# GD32E511_512 register map
File version: 1.0
CPU: CM33 r0p4, little endian, MPU, FPU, 4 interrupt priority bits
Registers are 32-bit, read-write, reset 0x0 unless marked. A register's access mark holds for its fields unless they carry their own. Offsets are from the block's base; [hi:lo] are bit positions.

## RCU — Reset and clock unit
Base 0x40021000
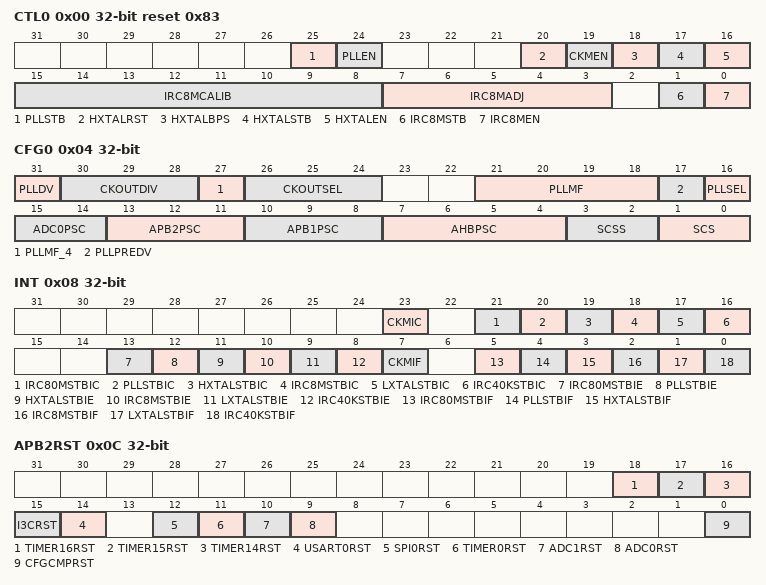
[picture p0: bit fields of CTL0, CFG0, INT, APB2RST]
0x00 CTL0 access per field reset 0x83 — Control register 0
  [25] PLLSTB ro — PLL clock stabilization flag
  [24] PLLEN rw — PLL enable
  [20] HXTALRST rw — HXTAL reset
  [19] CKMEN rw — HXTAL clock monitor enable
  [18] HXTALBPS rw — External crystal oscillator (HXTAL) clock bypass mode enable
  [17] HXTALSTB ro — External crystal oscillator (HXTAL) clock stabilization flag
  [16] HXTALEN rw — External high speed oscillator enable
  [15:8] IRC8MCALIB ro — Internal 8M RC oscillator calibration value register
  [7:3] IRC8MADJ rw — Internal 8M RC oscillator clock trim adjust value
  [1] IRC8MSTB ro — IRC8M high speed internal oscillator stabilization flag
  [0] IRC8MEN rw — Internal high speed oscillator enable
0x04 CFG0 access per field — Configuration register 0
  [31] PLLDV rw — The CK_PLL divide by 1 or 2 for CK_OUT
  [30:28] CKOUTDIV rw — The CK_OUT divider which the CK_OUT frequency can be reduced,
  [27] PLLMF_4 rw — Bit 4 of PLLMF register
  [26:24] CKOUTSEL rw — CK_OUT clock source selection
  [21:18] PLLMF rw — PLL multiply factor
  [17] PLLPREDV rw — HXTAL divider for PLL source clock selection. This bit is the same bit as bit PREDV[0] from RCU_CFG1. Refer to RCU_CFG1 PREDV bits description.
  [16] PLLSEL rw — PLL clock source selection
  [15:14] ADC0PSC rw — ADC0 clock prescaler selection
  [13:11] APB2PSC rw — APB2 prescaler selection
  [10:8] APB1PSC rw — APB1 prescaler selection
  [7:4] AHBPSC rw — AHB prescaler selection
  [3:2] SCSS ro — System clock switch status
  [1:0] SCS rw — System clock switch
0x08 INT access per field — Interrupt register
  [23] CKMIC wo — HXTAL clock stuck interrupt clear
  [21] IRC80MSTBIC wo — IRC80M stabilization interrupt clear
  [20] PLLSTBIC wo — PLL stabilization interrupt clear
  [19] HXTALSTBIC wo — HXTAL stabilization interrupt clear
  [18] IRC8MSTBIC wo — IRC8M stabilization interrupt clear
  [17] LXTALSTBIC wo — LXTAL stabilization interrupt clear
  [16] IRC40KSTBIC wo — IRC40K stabilization interrupt clear
  [13] IRC80MSTBIE rw — IRC80M stabilization interrupt enable
  [12] PLLSTBIE rw — PLL stabilization interrupt enable
  [11] HXTALSTBIE rw — HXTAL stabilization interrupt enable
  [10] IRC8MSTBIE rw — IRC8M stabilization interrupt enable
  [9] LXTALSTBIE rw — LXTAL stabilization interrupt enable
  [8] IRC40KSTBIE rw — IRC40K stabilization interrupt enable
  [7] CKMIF ro — HXTAL clock stuck interrupt flag
  [5] IRC80MSTBIF ro — IRC80M stabilization interrupt flag
  [4] PLLSTBIF ro — PLL stabilization interrupt flag
  [3] HXTALSTBIF ro — HXTAL stabilization interrupt flag
  [2] IRC8MSTBIF ro — IRC8M stabilization interrupt flag
  [1] LXTALSTBIF ro — LXTAL stabilization interrupt flag
  [0] IRC40KSTBIF ro — IRC40K stabilization interrupt flag
0x0C APB2RST — APB2 reset register
  [18] TIMER16RST — TIMER16 reset
  [17] TIMER15RST — TIMER15 reset
  [16] TIMER14RST — TIMER14 reset
  [15] I3CRST — I3C Reset
  [14] USART0RST — USART0 Reset
  [12] SPI0RST — SPI0 Reset
  [11] TIMER0RST — TIMER0 reset
  [10] ADC1RST — ADC1 reset
  [9] ADC0RST — ADC0 reset
  [0] CFGCMPRST — System configuration and comparator reset
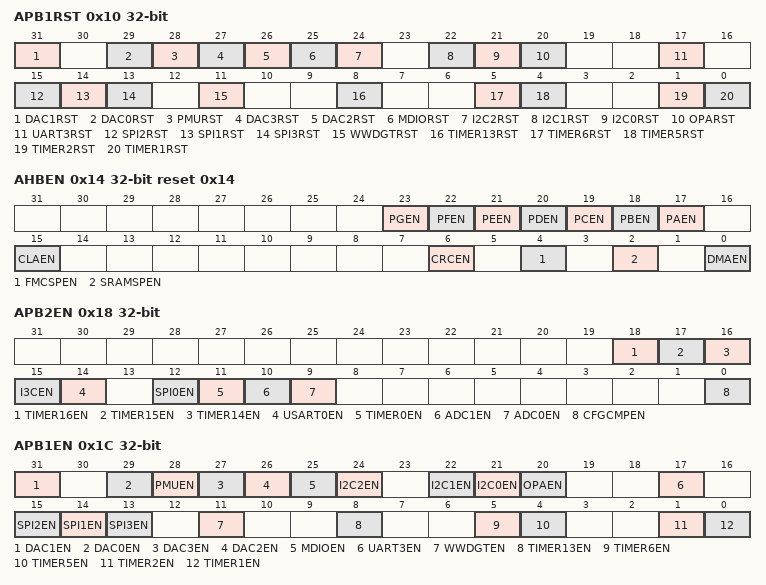
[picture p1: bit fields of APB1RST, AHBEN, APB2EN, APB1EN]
0x10 APB1RST — APB1 reset register
  [31] DAC1RST — DAC1 reset
  [29] DAC0RST — DAC0 reset
  [28] PMURST — Power control reset
  [27] DAC3RST — DAC3 reset
  [26] DAC2RST — DAC2 reset
  [25] MDIORST — MDIO reset
  [24] I2C2RST — I2C2 reset
  [22] I2C1RST — I2C1 reset
  [21] I2C0RST — I2C0 reset
  [20] OPARST — OPA reset
  [17] UART3RST — UART3 reset
  [15] SPI2RST — SPI2 reset
  [14] SPI1RST — SPI1 reset
  [13] SPI3RST — SPI3 reset
  [11] WWDGTRST — Window watchdog timer reset
  [8] TIMER13RST — TIMER13 timer reset
  [5] TIMER6RST — TIMER6 timer reset
  [4] TIMER5RST — TIMER5 timer reset
  [1] TIMER2RST — TIMER2 timer reset
  [0] TIMER1RST — TIMER1 timer reset
0x14 AHBEN reset 0x14 — AHB enable register
  [23] PGEN — GPIO port G clock enable
  [22] PFEN — GPIO port F clock enable
  [21] PEEN — GPIO port E clock enable
  [20] PDEN — GPIO port D clock enable
  [19] PCEN — GPIO port C clock enable
  [18] PBEN — GPIO port B clock enable
  [17] PAEN — GPIO port A clock enable
  [15] CLAEN — CLA clock enable
  [6] CRCEN — CRC clock enable
  [4] FMCSPEN — FMC clock enable
  [2] SRAMSPEN — SRAM interface clock enable
  [0] DMAEN — DMA clock enable
0x18 APB2EN — APB2 enable register
  [18] TIMER16EN — TIMER16 timer clock enable
  [17] TIMER15EN — TIMER15 timer clock enable
  [16] TIMER14EN — TIMER14 timer clock enable
  [15] I3CEN — I3C clock enable
  [14] USART0EN — USART0 clock enable
  [12] SPI0EN — SPI0 clock enable
  [11] TIMER0EN — TIMER0 timer clock enable
  [10] ADC1EN — ADC1 interface clock enable
  [9] ADC0EN — ADC0 interface clock enable
  [0] CFGCMPEN — System configuration and comparator clock enable
0x1C APB1EN — APB1 enable register
  [31] DAC1EN — DAC1 clock enable
  [29] DAC0EN — DAC0 clock enable
  [28] PMUEN — Power interface clock enable
  [27] DAC3EN — DAC3 clock enable
  [26] DAC2EN — DAC2 clock enable
  [25] MDIOEN — MDIO clock enable
  [24] I2C2EN — I2C2 clock enable
  [22] I2C1EN — I2C1 clock enable
  [21] I2C0EN — I2C0 clock enable
  [20] OPAEN — OPA clock enable
  [17] UART3EN — UART3 clock enable
  [15] SPI2EN — SPI2 clock enable
  [14] SPI1EN — SPI1 clock enable
  [13] SPI3EN — SPI3 clock enable
  [11] WWDGTEN — Window watchdog timer clock enable
  [8] TIMER13EN — TIMER13 timer clock enable
  [5] TIMER6EN — TIMER6 timer clock enable
  [4] TIMER5EN — TIMER5 timer clock enable
  [1] TIMER2EN — TIMER2 timer clock enable
  [0] TIMER1EN — TIMER1 timer clock enable
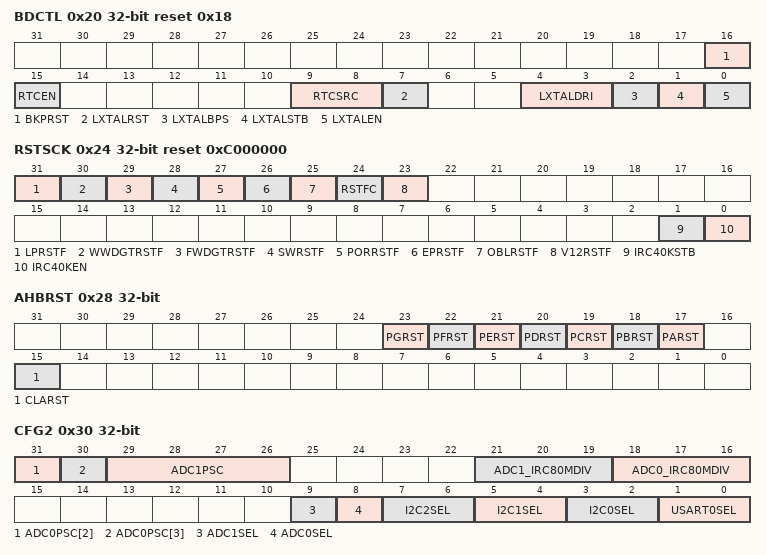
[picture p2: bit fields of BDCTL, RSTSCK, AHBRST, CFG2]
0x20 BDCTL access per field reset 0x18 — Backup domain control register
  [16] BKPRST rw — Backup domain reset
  [15] RTCEN rw — RTC clock enable
  [9:8] RTCSRC rw — RTC clock entry selection
  [7] LXTALRST rw — LXTAL reset
  [4:3] LXTALDRI rw — LXTAL drive capability
  [2] LXTALBPS rw — LXTAL bypass mode enable
  [1] LXTALSTB ro — External low-speed oscillator stabilization
  [0] LXTALEN rw — LXTAL enable
0x24 RSTSCK access per field reset 0xC000000 — Reset source /clock register
  [31] LPRSTF ro — Low-power reset flag
  [30] WWDGTRSTF ro — Window watchdog timer reset flag
  [29] FWDGTRSTF ro — Free Watchdog timer reset flag
  [28] SWRSTF ro — Software reset flag
  [27] PORRSTF ro — Power reset flag
  [26] EPRSTF ro — External pin reset flag
  [25] OBLRSTF ro — Option byte loader reset flag
  [24] RSTFC rw — Reset flag clear
  [23] V12RSTF ro — 1.2V domain Power reset flag
  [1] IRC40KSTB ro — IRC40K stabilization
  [0] IRC40KEN rw — IRC40K enable
0x28 AHBRST — AHB reset register
  [23] PGRST — GPIO port G reset
  [22] PFRST — GPIO port F reset
  [21] PERST — GPIO port E reset
  [20] PDRST — GPIO port D reset
  [19] PCRST — GPIO port C reset
  [18] PBRST — GPIO port B reset
  [17] PARST — GPIO port A reset
  [15] CLARST — CLA reset
0x2C CFG1 — Configuration register 1
  [3:0] PREDV — CK_HXTAL divider previous PLL
0x30 CFG2 — Configuration register 2
  [31] ADC0PSC[2] — Bit 2 of ADC0PSC
  [30] ADC0PSC[3] — Bit 3 of ADC0PSC
  [29:26] ADC1PSC — ADC1 clock prescaler selection
  [21:19] ADC1_IRC80MDIV — IRC80M divider or not for ADC1
  [18:16] ADC0_IRC80MDIV — IRC80M divider or not for ADC0
  [9] ADC1SEL — CK_ADC1 clock source selection
  [8] ADC0SEL — CK_ADC0 clock source selection
  [7:6] I2C2SEL — CK_I2C2 clock source selection
  [5:4] I2C1SEL — CK_I2C1 clock source selection
  [3:2] I2C0SEL — CK_I2C0 clock source selection
  [1:0] USART0SEL — CK_USART0 clock source selection
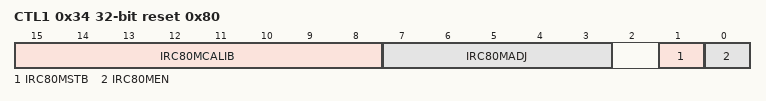
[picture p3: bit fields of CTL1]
0x34 CTL1 access per field reset 0x80 — Control register 1
  [15:8] IRC80MCALIB ro — Internal 80M RC Oscillator calibration value register
  [7:3] IRC80MADJ rw — Internal 80M RC Oscillator clock trim adjust value
  [1] IRC80MSTB ro — IRC80M Internal 80M RC Oscillator Stabilization Flag
  [0] IRC80MEN rw — IRC80M Internal 80M RC oscillator enable
0x100 VKEY wo — Voltage key register
  [31:0] KEY — The key of RCU_DSV register
0x134 DSV — Deep-sleep mode voltage register
  [1:0] DSLPVS — Deep-sleep mode voltage select
